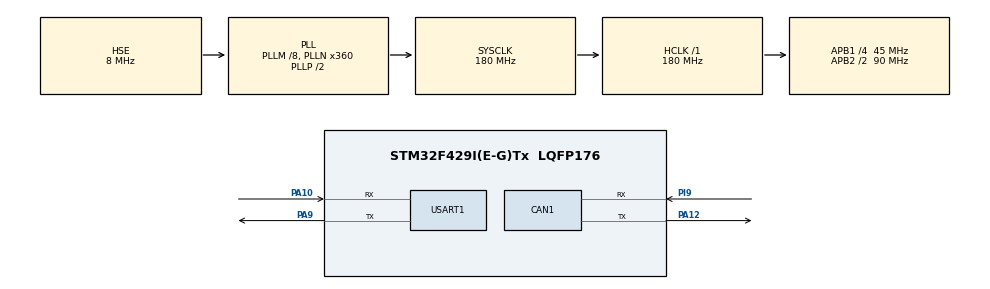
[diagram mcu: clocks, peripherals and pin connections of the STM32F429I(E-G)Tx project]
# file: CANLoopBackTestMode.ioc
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CAN1.CalculateTimeQuantum=355.55555555555554
Mcu.Family=STM32F4
Mcu.Name=STM32F429I(E-G)Tx
Mcu.Package=LQFP176
NVIC.PriorityGroup=NVIC_PRIORITYGROUP_4
PA10.Mode=Asynchronous
PA10.Signal=USART1_RX
PA12.Mode=Master
PA12.Signal=CAN1_TX
PA9.Mode=Asynchronous
PA9.Signal=USART1_TX
PH0/OSC_IN.Mode=HSE-External-Oscillator
PH0/OSC_IN.Signal=RCC_OSC_IN
PH1/OSC_OUT.Mode=HSE-External-Oscillator
PH1/OSC_OUT.Signal=RCC_OSC_OUT
PI9.Mode=Master
PI9.Signal=CAN1_RX
ProjectManager.HeapSize=0x200
ProjectManager.StackSize=0x400
ProjectManager.TargetToolchain=EWARM
RCC.48MHZClocksFreq_Value=90000000
RCC.AHBFreq_Value=180000000
RCC.APB1CLKDivider=RCC_HCLK_DIV4
RCC.APB1Freq_Value=45000000
RCC.APB1TimFreq_Value=90000000
RCC.APB2CLKDivider=RCC_HCLK_DIV2
RCC.APB2Freq_Value=90000000
RCC.APB2TimFreq_Value=180000000
RCC.CortexFreq_Value=180000000
RCC.HCLKFreq_Value=180000000
RCC.HSE_VALUE=8000000
RCC.HSI_VALUE=16000000
RCC.LSE_VALUE=32768
RCC.PLLM=8
RCC.PLLN=360
RCC.PLLSourceVirtual=RCC_PLLSOURCE_HSE
RCC.SYSCLKFreq_VALUE=180000000
RCC.SYSCLKSource=RCC_SYSCLKSOURCE_PLLCLK
RCC.VCOOutputFreq_Value=360000000
USART1.VirtualMode=VM_ASYNC
board=CANLoopBackTestMode

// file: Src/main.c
/**
  ******************************************************************************
  * @file           : main.c
  * @brief          : Main program body
  ******************************************************************************
  ** This notice applies to any and all portions of this file
  * that are not between comment pairs USER CODE BEGIN and
  * USER CODE END. Other portions of this file, whether
  * inserted by the user or by software development tools
  * are owned by their respective copyright owners.
  *
  * COPYRIGHT(c) 2019 STMicroelectronics
  *
  * Redistribution and use in source and binary forms, with or without modification,
  * are permitted provided that the following conditions are met:
  *   1. Redistributions of source code must retain the above copyright notice,
  *      this list of conditions and the following disclaimer.
  *   2. Redistributions in binary form must reproduce the above copyright notice,
  *      this list of conditions and the following disclaimer in the documentation
  *      and/or other materials provided with the distribution.
  *   3. Neither the name of STMicroelectronics nor the names of its contributors
  *      may be used to endorse or promote products derived from this software
  *      without specific prior written permission.
  *
  * THIS SOFTWARE IS PROVIDED BY THE COPYRIGHT HOLDERS AND CONTRIBUTORS "AS IS"
  * AND ANY EXPRESS OR IMPLIED WARRANTIES, INCLUDING, BUT NOT LIMITED TO, THE
  * IMPLIED WARRANTIES OF MERCHANTABILITY AND FITNESS FOR A PARTICULAR PURPOSE ARE
  * DISCLAIMED. IN NO EVENT SHALL THE COPYRIGHT HOLDER OR CONTRIBUTORS BE LIABLE
  * FOR ANY DIRECT, INDIRECT, INCIDENTAL, SPECIAL, EXEMPLARY, OR CONSEQUENTIAL
  * DAMAGES (INCLUDING, BUT NOT LIMITED TO, PROCUREMENT OF SUBSTITUTE GOODS OR
  * SERVICES; LOSS OF USE, DATA, OR PROFITS; OR BUSINESS INTERRUPTION) HOWEVER
  * CAUSED AND ON ANY THEORY OF LIABILITY, WHETHER IN CONTRACT, STRICT LIABILITY,
  * OR TORT (INCLUDING NEGLIGENCE OR OTHERWISE) ARISING IN ANY WAY OUT OF THE USE
  * OF THIS SOFTWARE, EVEN IF ADVISED OF THE POSSIBILITY OF SUCH DAMAGE.
  *
  ******************************************************************************
  */
#include "main.h"
#include "string.h"

#include "stm32f4xx_hal.h"

CAN_HandleTypeDef hcan1;

UART_HandleTypeDef huart1;

/* USER CODE BEGIN PV */
/* Private variables ---------------------------------------------------------*/

/* USER CODE END PV */

void SystemClock_Config(void);
static void MX_GPIO_Init(void);
static void MX_CAN1_Init(void);
static void MX_USART1_UART_Init(void);
// CAN Transmit Message
void CAN_Transmit(void);

/* USER CODE BEGIN PFP */
/* Private function prototypes -----------------------------------------------*/

/* USER CODE END PFP */

int main(void)
{

  /* MCU Configuration----------------------------------------------------------*/

  /* Reset of all peripherals, Initializes the Flash interface and the Systick. */
  HAL_Init();

  /* Configure the system clock */
  SystemClock_Config();

  /* Initialize all configured peripherals */
  MX_GPIO_Init();
  MX_CAN1_Init();
  MX_USART1_UART_Init();

  /* Infinite loop */
  while (1)
  {

  }

}

void SystemClock_Config(void)
{

  RCC_OscInitTypeDef RCC_OscInitStruct;
  RCC_ClkInitTypeDef RCC_ClkInitStruct;

    /**Configure the main internal regulator output voltage
    */
  __HAL_RCC_PWR_CLK_ENABLE();

  __HAL_PWR_VOLTAGESCALING_CONFIG(PWR_REGULATOR_VOLTAGE_SCALE1);

    /**Initializes the CPU, AHB and APB busses clocks
    */
  RCC_OscInitStruct.OscillatorType = RCC_OSCILLATORTYPE_HSE;
  RCC_OscInitStruct.HSEState = RCC_HSE_ON;
  RCC_OscInitStruct.PLL.PLLState = RCC_PLL_ON;
  RCC_OscInitStruct.PLL.PLLSource = RCC_PLLSOURCE_HSE;
  RCC_OscInitStruct.PLL.PLLM = 8;
  RCC_OscInitStruct.PLL.PLLN = 360;
  RCC_OscInitStruct.PLL.PLLP = RCC_PLLP_DIV2;
  RCC_OscInitStruct.PLL.PLLQ = 4;
  if (HAL_RCC_OscConfig(&RCC_OscInitStruct) != HAL_OK)
  {
    _Error_Handler(__FILE__, __LINE__);
  }

    /**Activate the Over-Drive mode
    */
  if (HAL_PWREx_EnableOverDrive() != HAL_OK)
  {
    _Error_Handler(__FILE__, __LINE__);
  }

    /**Initializes the CPU, AHB and APB busses clocks
    */
  RCC_ClkInitStruct.ClockType = RCC_CLOCKTYPE_HCLK|RCC_CLOCKTYPE_SYSCLK
                              |RCC_CLOCKTYPE_PCLK1|RCC_CLOCKTYPE_PCLK2;
  RCC_ClkInitStruct.SYSCLKSource = RCC_SYSCLKSOURCE_PLLCLK;
  RCC_ClkInitStruct.AHBCLKDivider = RCC_SYSCLK_DIV1;
  RCC_ClkInitStruct.APB1CLKDivider = RCC_HCLK_DIV4;
  RCC_ClkInitStruct.APB2CLKDivider = RCC_HCLK_DIV2;

  if (HAL_RCC_ClockConfig(&RCC_ClkInitStruct, FLASH_LATENCY_5) != HAL_OK)
  {
    _Error_Handler(__FILE__, __LINE__);
  }

    /**Configure the Systick interrupt time
    */
  HAL_SYSTICK_Config(HAL_RCC_GetHCLKFreq()/1000);

    /**Configure the Systick
    */
  HAL_SYSTICK_CLKSourceConfig(SYSTICK_CLKSOURCE_HCLK);

  /* SysTick_IRQn interrupt configuration */
  HAL_NVIC_SetPriority(SysTick_IRQn, 0, 0);
}

/* CAN1 init function for 1000  */
static void MX_CAN1_Init(void)
{

  // Setting related to CAN
  hcan1.Instance = CAN1;
  hcan1.Init.Mode = CAN_MODE_LOOPBACK;
  hcan1.Init.TimeTriggeredMode = DISABLE;
  hcan1.Init.AutoBusOff = DISABLE;
  hcan1.Init.AutoWakeUp = DISABLE;
  hcan1.Init.AutoRetransmission = ENABLE;
  hcan1.Init.ReceiveFifoLocked = DISABLE;
  hcan1.Init.TransmitFifoPriority = DISABLE;
  // Setting related to CAN bit timings
  hcan1.Init.Prescaler = 3;
  hcan1.Init.SyncJumpWidth = CAN_SJW_1TQ;
  hcan1.Init.TimeSeg1 = CAN_BS1_12TQ;
  hcan1.Init.TimeSeg2 = CAN_BS2_1TQ;

  if (HAL_CAN_Init(&hcan1) != HAL_OK)
  {
    _Error_Handler(__FILE__, __LINE__);
  }

}

/* USART1 init function */
static void MX_USART1_UART_Init(void)
{

  huart1.Instance = USART1;
  huart1.Init.BaudRate = 115200;
  huart1.Init.WordLength = UART_WORDLENGTH_8B;
  huart1.Init.StopBits = UART_STOPBITS_1;
  huart1.Init.Parity = UART_PARITY_NONE;
  huart1.Init.Mode = UART_MODE_TX_RX;
  huart1.Init.HwFlowCtl = UART_HWCONTROL_NONE;
  huart1.Init.OverSampling = UART_OVERSAMPLING_16;
  if (HAL_UART_Init(&huart1) != HAL_OK)
  {
    _Error_Handler(__FILE__, __LINE__);
  }

}

/** Configure pins as
        * Analog
        * Input
        * Output
        * EVENT_OUT
        * EXTI
*/
static void MX_GPIO_Init(void)
{

  /* GPIO Ports Clock Enable */
  __HAL_RCC_GPIOI_CLK_ENABLE();
  __HAL_RCC_GPIOH_CLK_ENABLE();
  __HAL_RCC_GPIOA_CLK_ENABLE();

}

/* USER CODE BEGIN 4 */
void CAN_Transmit(void)
{
  CAN_TxHeaderTypeDef txHeader;

  // Message to be sent
  uint8_t message[5]= {'H','E','L','L','O'};
  char msg[50];
  uint32_t txMailbox;

  txHeader.DLC = 5;
  txHeader.StdId = 0x65D;
  txHeader.IDE = CAN_ID_STD;
  txHeader.RTR = CAN_RTR_DATA;
    // txMailbox is updated here
    if (HAL_CAN_AddTxMessage(&hcan1, &txHeader, message, &txMailbox) != HAL_OK)
    {
      _Error_Handler(__FILE__, __LINE__);
    }
    // Wait until the message will be transmitted completly
    while(HAL_CAN_IsTxMessagePending(&hcan1, txMailbox));

    sprintf(msg, "Message Transmitted\r\n");
    HAL_UART_Transmit(&huart1, (uint8_t*)msg, strlen(msg), HAL_MAX_DELAY);

}
/* USER CODE END 4 */

void _Error_Handler(char *file, int line)
{
  while(1)
  {
  }
}

/************************ (C) COPYRIGHT STMicroelectronics *****END OF FILE****/
